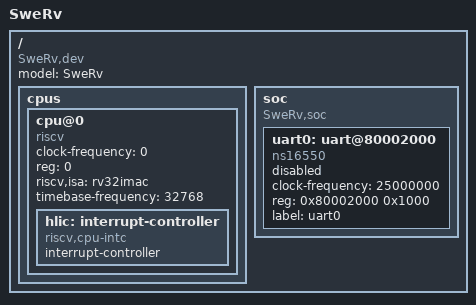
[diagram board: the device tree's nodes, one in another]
/* SPDX-License-Identifier: Apache-2.0 */

#include <dt-bindings/gpio/gpio.h>

/ {
	#address-cells = <1>;
	#size-cells = <1>;
	compatible = "SweRv,dev";
	model = "SweRv";
	cpus {
		#address-cells = <1>;
		#size-cells = <0>;
		cpu@0 {
			clock-frequency = <0>;
			compatible = "riscv";
			device_type = "cpu";
			reg = <0>;
			riscv,isa = "rv32imac";
			status = "okay";
			timebase-frequency = <32768>;
			hlic: interrupt-controller {
				#interrupt-cells = <1>;
				compatible = "riscv,cpu-intc";
				interrupt-controller;
			};
		};
	};
	soc {
		#address-cells = <1>;
		#size-cells = <1>;
		compatible = "SweRv,soc", "simple-bus";
		ranges;
		uart0: uart@80002000 {
			compatible = "ns16550";
			clock-frequency = <25000000>;
			reg = <0x80002000 0x1000>;
			reg-names = "control";
			label = "uart0";
			status = "disabled";
		};
	};
};
